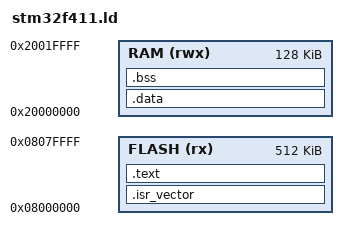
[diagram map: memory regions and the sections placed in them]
/* Minimal linker script for STM32F411 */
MEMORY
{
    FLASH (rx)  : ORIGIN = 0x08000000, LENGTH = 512K
    RAM   (rwx) : ORIGIN = 0x20000000, LENGTH = 128K
}

SECTIONS
{
    .isr_vector : {
        KEEP(*(.isr_vector))
        . = ALIGN(4);
    } > FLASH

    .text : {
        . = ALIGN(4);
        *(.text*)
        *(.rodata*)
        . = ALIGN(4);
    } > FLASH

    _sidata = .;

    .data : AT(_sidata) {
        . = ALIGN(4);
        _sdata = .;
        *(.data*)
        . = ALIGN(4);
        _edata = .;
    } > RAM

    .bss : {
        . = ALIGN(4);
        _sbss = .;
        *(.bss*)
        *(COMMON)
        . = ALIGN(4);
        _ebss = .;
    } > RAM

    _estack = ORIGIN(RAM) + LENGTH(RAM);
}
